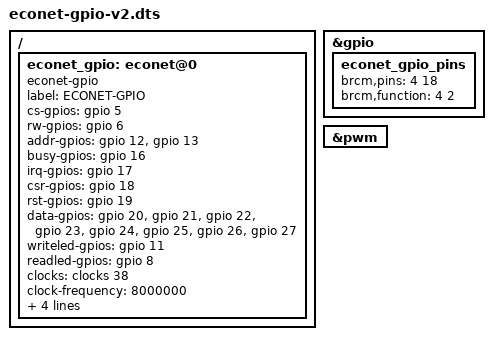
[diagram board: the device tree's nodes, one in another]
/*
  (c) 2022 Chris Royle
    This program is free software: you can redistribute it and/or modify
    it under the terms of the GNU General Public License as published by
    the Free Software Foundation, either version 3 of the License, or
    (at your option) any later version.

    This program is distributed in the hope that it will be useful,
    but WITHOUT ANY WARRANTY; without even the implied warranty of
    MERCHANTABILITY or FITNESS FOR A PARTICULAR PURPOSE.  See the
    GNU General Public License for more details.

    You should have received a copy of the GNU General Public License
    along with this program.  If not, see <https://www.gnu.org/licenses/>.
*/

/dts-v1/;
/plugin/;


/ {


	/* Create an econet-gpio driver instance */

	fragment@0 {
		/* compatible = "brcm,bcm2711", "brcm,bcm2837", "brcm,bcm2710"; OLD */
		compatible = "raspberrypi,model-zero",
			"raspberrypi,model-zero-w",
			"raspberrypi,3-model-b-plus",
			"raspberrypi,4-model-b",
			"raspberrypi,400",
			"raspberrypi,4-compute-module",
			"raspberrypi,model-zero-2-w",
			"raspberrypi,model-zero-2";
		target-path = "/";
		__overlay__ {
			econet_gpio: econet@0 {
				label = "ECONET-GPIO";
				compatible = "econet-gpio";

				/* Pins in use */

				/* clk-gpios = <&gpio 4 0>; */
				cs-gpios = <&gpio 5 0>;
				rw-gpios = <&gpio 6 0>;
				addr-gpios = <&gpio 12 0>, <&gpio 13 0>;
				busy-gpios = <&gpio 16 0>;
				irq-gpios = <&gpio 17 0>;
				csr-gpios = <&gpio 18 0>;
				rst-gpios = <&gpio 19 0>;
				data-gpios = <&gpio 20 0>, 
						<&gpio 21 0>,
						<&gpio 22 0>,
						<&gpio 23 0>,
						<&gpio 24 0>,
						<&gpio 25 0>,
						<&gpio 26 0>,
						<&gpio 27 0>;
				writeled-gpios = <&gpio 11 0>;
				readled-gpios = <&gpio 8 0>;
		
				/* ADLC Clock */
				clocks = <&clocks 38>;
				clock-frequency = <8000000>;

				/* Econet clock */
				pwms = <&pwm 0 4000000 0>;
				pwm-names = "netclk";

				/* Pinctrl */
				pinctrl-names = "default";
				pinctrl-0 = <&econet_gpio_pins>;

				/* Board version */
				version = /bits/ 8 < 0x02 >;

				status = "okay";
			};
		};
	};

	/* Fragment to set up ALT modes for GPIO4 (GPCLK0, ALT0, ADLC Clock) and GPIO18 (PWM0, ALT5, Econet Clock) */

        fragment@1 {
                target = <&gpio>;
                __overlay__ {
                        econet_gpio_pins: econet_gpio_pins {
                                brcm,pins = <4 18>;
                                brcm,function = <4 2>;// pin 4 GPCLCK0 (ALT0), pin 18 PWM0 (ALT 5)
                        };
                };
        };

	/* Turn on the PWM driver */

        fragment@2 {
                target = <&pwm>;
                __overlay__ {
                        status = "okay";
                };
        };

};


